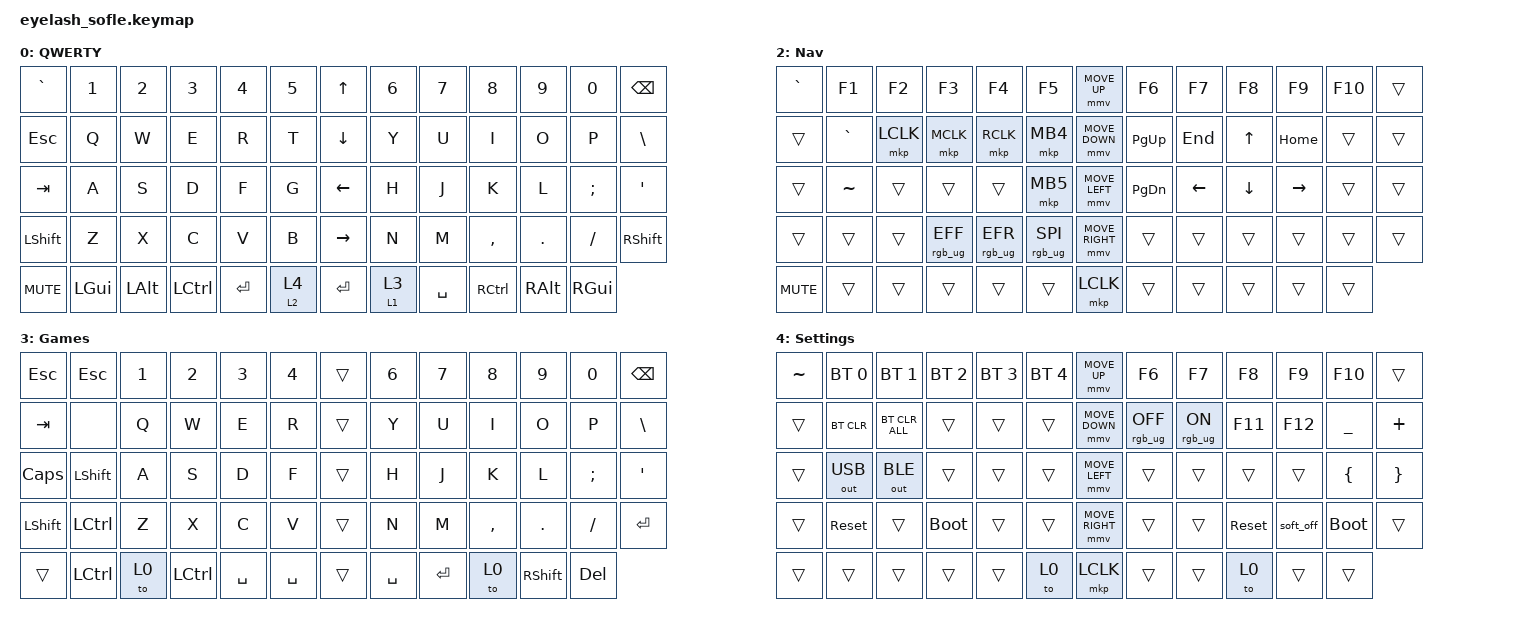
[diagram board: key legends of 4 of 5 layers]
#define ZMK_POINTING_DEFAULT_MOVE_VAL 600
#define ZMK_POINTING_DEFAULT_SCRL_VAL 25   // 10

#include <input/processors.dtsi>
#include <zephyr/dt-bindings/input/input-event-codes.h>
#include <behaviors.dtsi>
#include <dt-bindings/zmk/bt.h>
#include <dt-bindings/zmk/ext_power.h>
#include <dt-bindings/zmk/keys.h>
#include <dt-bindings/zmk/pointing.h>
#include <dt-bindings/zmk/rgb.h>
#include <dt-bindings/zmk/outputs.h>

&mmv_input_listener { input-processors = <&zip_xy_scaler 2 1>; };

&msc_input_listener { input-processors = <&zip_scroll_scaler 2 1>; };

#define MO_TO(layer) &mo_to layer layer

// &msc {
//     acceleration-exponent = <1>;      // 0
//     time-to-max-speed-ms = <100>;       // 300
//     delay-ms = <0>;                   // 0
// };

// &mmv {
//     time-to-max-speed-ms = <500>;
//     acceleration-exponent = <1>;
//     trigger-period-ms = <16>;
// };


/ {
    behaviors {
        mo_to: behavior_mo_to {
            compatible = "zmk,behavior-hold-tap";
            #binding-cells = <2>;
            flavor = "hold-preferred";
            tapping-term-ms = <200>;
            bindings = <&mo>, <&to>;
        };

        mmv {
            acceleration-exponent = <1>;      // 1
            time-to-max-speed-ms = <900>;    // 40
            delay-ms = <10>;                   // 0
            max-speed = <400>;
        };

        msc {
            acceleration-exponent = <1>;      // 0
            time-to-max-speed-ms = <400>;      // 500
            delay-ms = <0>;                   //   10
        };                                          
    };

    scroll_encoder: scroll_encoder {
        compatible = "zmk,behavior-sensor-rotate";
        #sensor-binding-cells = <0>;
        bindings = <&msc SCRL_DOWN>, <&msc SCRL_UP>;
        tap-ms = <100>;
    };

    keymap {
        compatible = "zmk,keymap";
        

        layer0 {
            display-name = "QWERTY";
            bindings = <
&kp GRAVE   &kp N1     &kp N2        &kp N3        &kp N4  &kp N5       &kp UP_ARROW     &kp N6     &kp N7     &kp N8     &kp N9           &kp N0      &kp BACKSPACE
&kp ESC     &kp Q          &kp W         &kp E         &kp R   &kp T        &kp DOWN_ARROW   &kp Y      &kp U      &kp I      &kp O            &kp P       &kp BSLH
&kp TAB     &kp A         &kp S         &kp D         &kp F   &kp G        &kp LEFT_ARROW   &kp H      &kp J      &kp K      &kp L            &kp SEMI    &kp SQT
&kp LSHFT   &kp Z           &kp X         &kp C         &kp V   &kp B        &kp RIGHT_ARROW  &kp N      &kp M      &kp COMMA  &kp DOT          &kp FSLH    &kp RSHFT
&kp C_MUTE  &kp LEFT_GUI  &kp LALT  &kp LCTRL   &kp RET  &mo_to 2 4         &kp ENTER       &mo_to 1 3  &kp SPACE  &kp RCTRL  &kp RALT      &kp RGUI  
            >;

            sensor-bindings = <&inc_dec_kp C_VOLUME_UP C_VOL_DN>;
        };

        layer_1 {
            display-name = "Symbols";

            bindings = <
&kp GRAVE   &kp F1           &kp F2          &kp F3           &kp F4           &kp F5             &mmv MOVE_UP     &kp F6    &kp F7   &kp F8    &kp F9    &kp F10   &kp F11
&trans      &kp N2    &kp N3      &kp N4    &kp N5                                              &mmv MOVE_DOWN   &kp N6    &kp N7   &kp N8    &kp N9    &kp N0    &kp F12
&trans      &kp EXCL        &kp AT    &kp HASH    &kp DLLR  &kp PRCNT                           &mmv MOVE_LEFT   &kp CARET &kp AMPS &kp ASTRK &kp LPAR  &kp RPAR  &kp PIPE
&trans      &kp EQUAL  &kp MINUS &kp PLUS &kp LBRC  &kp RBRC                                     &mmv MOVE_RIGHT  &kp LBKT  &kp RBKT &kp SEMI  &kp COLON &kp BSLH  &trans
&kp C_MUTE  &trans           &trans          &trans           &trans           &trans             &mkp LCLK        &to 0          &trans           &trans      &trans     &trans
            >;

            sensor-bindings = <&scroll_encoder>;
        };

        layer_2 {
            display-name = "Nav";

            bindings = <
&kp GRAVE   &kp F1           &kp F2          &kp F3           &kp F4           &kp F5             &mmv MOVE_UP     &kp F6           &kp F7           &kp F8      &kp F9     &kp F10           &trans
&trans      &kp GRAVE        &mkp LCLK       &mkp MCLK        &mkp RCLK        &mkp MB4           &mmv MOVE_DOWN   &kp PG_UP        &kp END          &kp UP      &kp HOME   &trans           &trans
&trans      &kp TILDE        &trans          &trans           &trans           &mkp MB5           &mmv MOVE_LEFT   &kp PG_DN        &kp LEFT         &kp DOWN    &kp RIGHT  &trans           &trans 
&trans      &trans           &trans  &rgb_ug RGB_EFF  &rgb_ug RGB_EFR  &rgb_ug RGB_SPI    &mmv MOVE_RIGHT  &trans &trans  &trans           &trans      &trans          &trans
&kp C_MUTE  &trans           &trans          &trans           &trans           &trans             &mkp LCLK        &trans           &trans           &trans      &trans     &trans
            >;

            sensor-bindings = <&scroll_encoder>;
        };

        layer_3 {
            display-name = "Games";
            bindings = <
                &kp ESC     &kp ESC      &kp N1       &kp N2     &kp N3      &kp N4    &trans     &kp N6     &kp N7     &kp N8     &kp N9     &kp N0      &kp BACKSPACE
                &kp TAB     &none       &kp Q        &kp W      &kp E       &kp R         &trans  &kp Y      &kp U      &kp I      &kp O      &kp P       &kp BSLH
                &kp CAPS    &kp LSHFT     &kp A        &kp S      &kp D       &kp F         &trans  &kp H      &kp J      &kp K      &kp L      &kp SEMI    &kp APOS
                &kp LSHFT   &kp LCTRL   &kp Z        &kp X      &kp C       &kp V         &trans  &kp N      &kp M      &kp COMMA  &kp DOT    &kp FSLH    &kp ENTER
                &trans      &kp LCTRL   &to 0        &kp LCTRL  &kp SPACE &kp SPACE      &trans   &kp SPACE  &kp ENTER  &to 0      &kp RIGHT_SHIFT  &kp DELETE
            >;

            sensor-bindings = <&scroll_encoder>;
        };

        layer_4 {
            display-name = "Settings";
            bindings = <
&kp TILDE  &bt BT_SEL 0  &bt BT_SEL 1    &bt BT_SEL 2  &bt BT_SEL 3  &bt BT_SEL 4    &mmv MOVE_UP     &kp F6  &kp F7  &kp F8      &kp F9     &kp F10      &trans
&trans     &bt BT_CLR    &bt BT_CLR_ALL  &trans        &trans        &trans          &mmv MOVE_DOWN   &rgb_ug RGB_OFF  &rgb_ug RGB_ON  &kp F11     &kp F12    &kp UNDER    &kp PLUS
&trans     &out OUT_USB  &out OUT_BLE    &trans        &trans        &trans          &mmv MOVE_LEFT   &trans  &trans  &trans      &trans     &kp LBRC     &kp RBRC
&trans     &sys_reset    &trans          &bootloader   &trans        &trans          &mmv MOVE_RIGHT  &trans  &trans  &sys_reset  &soft_off  &bootloader  &trans
&trans     &trans        &trans          &trans        &trans        &to 0           &mkp LCLK        &trans  &trans  &to 0      &trans     &trans
            >;

            sensor-bindings = <&scroll_encoder>;
        };
    };
};
